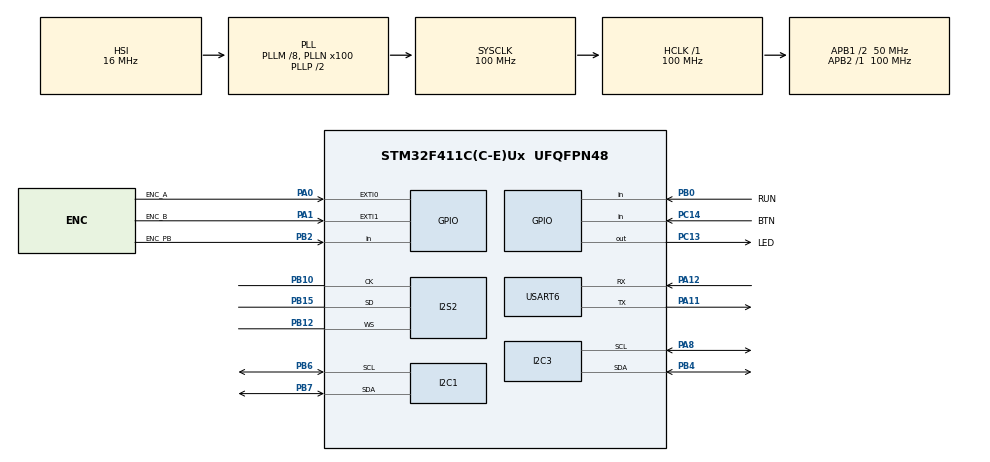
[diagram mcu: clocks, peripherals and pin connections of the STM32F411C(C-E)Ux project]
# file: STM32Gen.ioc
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Dma.Request0=SPI2_TX
Dma.SPI2_TX.0.Direction=DMA_MEMORY_TO_PERIPH
Dma.SPI2_TX.0.FIFOMode=DMA_FIFOMODE_DISABLE
Dma.SPI2_TX.0.Instance=DMA1_Stream4
Dma.SPI2_TX.0.MemDataAlignment=DMA_MDATAALIGN_HALFWORD
Dma.SPI2_TX.0.MemInc=DMA_MINC_ENABLE
Dma.SPI2_TX.0.Mode=DMA_CIRCULAR
Dma.SPI2_TX.0.PeriphDataAlignment=DMA_PDATAALIGN_HALFWORD
Dma.SPI2_TX.0.PeriphInc=DMA_PINC_DISABLE
Dma.SPI2_TX.0.Priority=DMA_PRIORITY_LOW
FREERTOS.Tasks01=defaultTask,24,512,StartDefaultTask,Default,NULL,Static,defaultTaskBuffer,defaultTaskControlBlock;waveGenTask,32,512,StartWaveGenTask,Default,NULL,Static,waveGenTaskBuffer,waveGenTaskControlBlock
FREERTOS.configUSE_NEWLIB_REENTRANT=1
I2C1.I2C_Mode=I2C_Fast
I2S2.AudioFreq=AudioFreqCustomValue
I2S2.AudioFreqCustom=40000
I2S2.ErrorAudioFreq=0.0 %
I2S2.FullDuplexMode=I2S_FULLDUPLEXMODE_DISABLE
I2S2.Instance=SPI$Index
I2S2.RealAudioFreq=40.0 KHz
I2S2.VirtualMode=I2S_MODE_MASTER
Mcu.Family=STM32F4
Mcu.Name=STM32F411C(C-E)Ux
Mcu.Package=UFQFPN48
NVIC.DMA1_Stream4_IRQn=true\:5\:0\:false\:false\:true\:true\:false\:true\:true
NVIC.EXTI0_IRQn=true\:5\:0\:false\:false\:true\:true\:true\:true\:true
NVIC.EXTI1_IRQn=true\:5\:0\:false\:false\:true\:true\:true\:true\:true
NVIC.PriorityGroup=NVIC_PRIORITYGROUP_4
NVIC.TIM1_UP_TIM10_IRQn=true\:15\:0\:false\:false\:true\:false\:false\:true\:true
NVIC.TimeBase=TIM1_UP_TIM10_IRQn
NVIC.TimeBaseIP=TIM10
PA0-WKUP.GPIO_Label=ENC_A
PA0-WKUP.GPIO_ModeDefaultEXTI=GPIO_MODE_IT_RISING_FALLING
PA0-WKUP.Signal=GPXTI0
PA1.GPIO_Label=ENC_B
PA1.GPIO_ModeDefaultEXTI=GPIO_MODE_IT_RISING_FALLING
PA1.Signal=GPXTI1
PA11.Mode=Asynchronous
PA11.Signal=USART6_TX
PA12.Mode=Asynchronous
PA12.Signal=USART6_RX
PA13.Mode=Serial_Wire
PA13.Signal=SYS_JTMS-SWDIO
PA14.Mode=Serial_Wire
PA14.Signal=SYS_JTCK-SWCLK
PA8.Mode=I2C
PA8.Signal=I2C3_SCL
PB0.GPIO_Label=RUN
PB0.GPIO_PuPd=GPIO_PULLDOWN
PB0.Signal=GPIO_Input
PB10.Mode=Half_Duplex_Master
PB10.Signal=I2S2_CK
PB12.Mode=Half_Duplex_Master
PB12.Signal=I2S2_WS
PB15.Mode=Half_Duplex_Master
PB15.Signal=I2S2_SD
PB2.GPIO_Label=ENC_PB
PB2.Signal=GPIO_Input
PB4.Mode=I2C
PB4.Signal=I2C3_SDA
PB6.Mode=I2C
PB6.Signal=I2C1_SCL
PB7.Mode=I2C
PB7.Signal=I2C1_SDA
PC13-ANTI_TAMP.GPIO_Label=LED
PC13-ANTI_TAMP.Signal=GPIO_Output
PC14-OSC32_IN.GPIO_Label=BTN
PC14-OSC32_IN.Signal=GPIO_Input
PH0\ -\ OSC_IN.Mode=HSE-External-Oscillator
PH0\ -\ OSC_IN.Signal=RCC_OSC_IN
PH1\ -\ OSC_OUT.Mode=HSE-External-Oscillator
PH1\ -\ OSC_OUT.Signal=RCC_OSC_OUT
ProjectManager.HeapSize=0x200
ProjectManager.StackSize=0x400
ProjectManager.TargetToolchain=STM32CubeIDE
RCC.48MHZClocksFreq_Value=50000000
RCC.AHBFreq_Value=100000000
RCC.APB1CLKDivider=RCC_HCLK_DIV2
RCC.APB1Freq_Value=50000000
RCC.APB1TimFreq_Value=100000000
RCC.APB2Freq_Value=100000000
RCC.APB2TimFreq_Value=100000000
RCC.CortexFreq_Value=100000000
RCC.HCLKFreq_Value=100000000
RCC.HSE_VALUE=25000000
RCC.HSI_VALUE=16000000
RCC.LSE_VALUE=32768
RCC.PLLM=8
RCC.PLLN=100
RCC.SYSCLKFreq_VALUE=100000000
RCC.SYSCLKSource=RCC_SYSCLKSOURCE_PLLCLK
RCC.VCOOutputFreq_Value=200000000
USART6.VirtualMode=VM_ASYNC
VP_FREERTOS_VS_CMSIS_V2.Mode=CMSIS_V2
VP_SYS_VS_tim10.Mode=TIM10
board=custom

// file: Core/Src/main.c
/* USER CODE BEGIN Header */
/**
  ******************************************************************************
  * @file           : main.c
  * @brief          : Main program body
  ******************************************************************************
  * @attention
  *
  * Copyright (c) 2026 STMicroelectronics.
  * All rights reserved.
  *
  * This software is licensed under terms that can be found in the LICENSE file
  * in the root directory of this software component.
  * If no LICENSE file comes with this software, it is provided AS-IS.
  *
  ******************************************************************************
  */
/* USER CODE END Header */
#include "main.h"
#include "cmsis_os.h"

/* USER CODE BEGIN Includes */
#include <stdio.h>

#include "DefaultTask.h"
#include "WaveGenTask.h"
/* USER CODE END Includes */

typedef StaticTask_t osStaticThreadDef_t;

I2C_HandleTypeDef hi2c1;
I2C_HandleTypeDef hi2c3;

I2S_HandleTypeDef hi2s2;
DMA_HandleTypeDef hdma_spi2_tx;

UART_HandleTypeDef huart6;

/* Definitions for defaultTask */
osThreadId_t defaultTaskHandle;
uint32_t defaultTaskBuffer[ 512 ];
osStaticThreadDef_t defaultTaskControlBlock;
const osThreadAttr_t defaultTask_attributes = {
  .name = "defaultTask",
  .cb_mem = &defaultTaskControlBlock,
  .cb_size = sizeof(defaultTaskControlBlock),
  .stack_mem = &defaultTaskBuffer[0],
  .stack_size = sizeof(defaultTaskBuffer),
  .priority = (osPriority_t) osPriorityNormal,
};
/* Definitions for waveGenTask */
osThreadId_t waveGenTaskHandle;
uint32_t waveGenTaskBuffer[ 512 ];
osStaticThreadDef_t waveGenTaskControlBlock;
const osThreadAttr_t waveGenTask_attributes = {
  .name = "waveGenTask",
  .cb_mem = &waveGenTaskControlBlock,
  .cb_size = sizeof(waveGenTaskControlBlock),
  .stack_mem = &waveGenTaskBuffer[0],
  .stack_size = sizeof(waveGenTaskBuffer),
  .priority = (osPriority_t) osPriorityAboveNormal,
};

void SystemClock_Config(void);
static void MX_GPIO_Init(void);
static void MX_DMA_Init(void);
static void MX_I2C1_Init(void);
static void MX_I2S2_Init(void);
static void MX_I2C3_Init(void);
static void MX_USART6_UART_Init(void);
void StartDefaultTask(void *argument);
void StartWaveGenTask(void *argument);

int main(void)
{

  /* MCU Configuration--------------------------------------------------------*/

  /* Reset of all peripherals, Initializes the Flash interface and the Systick. */
  HAL_Init();

  /* Configure the system clock */
  SystemClock_Config();

  /* Initialize all configured peripherals */
  MX_GPIO_Init();
  MX_DMA_Init();
  MX_I2C1_Init();
  MX_I2S2_Init();
  MX_I2C3_Init();
  MX_USART6_UART_Init();
  /* USER CODE BEGIN 2 */

  puts( "\x0cStarted\r\n" );
  fflush( stdout );
  /* USER CODE END 2 */

  /* Init scheduler */
  osKernelInitialize();

  /* Create the thread(s) */
  /* creation of defaultTask */
  defaultTaskHandle = osThreadNew(StartDefaultTask, NULL, &defaultTask_attributes);

  /* creation of waveGenTask */
  waveGenTaskHandle = osThreadNew(StartWaveGenTask, NULL, &waveGenTask_attributes);

  /* Start scheduler */
  osKernelStart();

  /* We should never get here as control is now taken by the scheduler */

  /* Infinite loop */
  while (1)
  {

  }
}

void SystemClock_Config(void)
{
  RCC_OscInitTypeDef RCC_OscInitStruct = {0};
  RCC_ClkInitTypeDef RCC_ClkInitStruct = {0};

  /** Configure the main internal regulator output voltage
  */
  __HAL_RCC_PWR_CLK_ENABLE();
  __HAL_PWR_VOLTAGESCALING_CONFIG(PWR_REGULATOR_VOLTAGE_SCALE1);

  /** Initializes the RCC Oscillators according to the specified parameters
  * in the RCC_OscInitTypeDef structure.
  */
  RCC_OscInitStruct.OscillatorType = RCC_OSCILLATORTYPE_HSI;
  RCC_OscInitStruct.HSIState = RCC_HSI_ON;
  RCC_OscInitStruct.HSICalibrationValue = RCC_HSICALIBRATION_DEFAULT;
  RCC_OscInitStruct.PLL.PLLState = RCC_PLL_ON;
  RCC_OscInitStruct.PLL.PLLSource = RCC_PLLSOURCE_HSI;
  RCC_OscInitStruct.PLL.PLLM = 8;
  RCC_OscInitStruct.PLL.PLLN = 100;
  RCC_OscInitStruct.PLL.PLLP = RCC_PLLP_DIV2;
  RCC_OscInitStruct.PLL.PLLQ = 4;
  if (HAL_RCC_OscConfig(&RCC_OscInitStruct) != HAL_OK)
  {
    Error_Handler();
  }

  /** Initializes the CPU, AHB and APB buses clocks
  */
  RCC_ClkInitStruct.ClockType = RCC_CLOCKTYPE_HCLK|RCC_CLOCKTYPE_SYSCLK
                              |RCC_CLOCKTYPE_PCLK1|RCC_CLOCKTYPE_PCLK2;
  RCC_ClkInitStruct.SYSCLKSource = RCC_SYSCLKSOURCE_PLLCLK;
  RCC_ClkInitStruct.AHBCLKDivider = RCC_SYSCLK_DIV1;
  RCC_ClkInitStruct.APB1CLKDivider = RCC_HCLK_DIV2;
  RCC_ClkInitStruct.APB2CLKDivider = RCC_HCLK_DIV1;

  if (HAL_RCC_ClockConfig(&RCC_ClkInitStruct, FLASH_LATENCY_3) != HAL_OK)
  {
    Error_Handler();
  }
}

static void MX_I2C1_Init(void)
{

  hi2c1.Instance = I2C1;
  hi2c1.Init.ClockSpeed = 400000;
  hi2c1.Init.DutyCycle = I2C_DUTYCYCLE_2;
  hi2c1.Init.OwnAddress1 = 0;
  hi2c1.Init.AddressingMode = I2C_ADDRESSINGMODE_7BIT;
  hi2c1.Init.DualAddressMode = I2C_DUALADDRESS_DISABLE;
  hi2c1.Init.OwnAddress2 = 0;
  hi2c1.Init.GeneralCallMode = I2C_GENERALCALL_DISABLE;
  hi2c1.Init.NoStretchMode = I2C_NOSTRETCH_DISABLE;
  if (HAL_I2C_Init(&hi2c1) != HAL_OK)
  {
    Error_Handler();
  }

}

static void MX_I2C3_Init(void)
{

  hi2c3.Instance = I2C3;
  hi2c3.Init.ClockSpeed = 100000;
  hi2c3.Init.DutyCycle = I2C_DUTYCYCLE_2;
  hi2c3.Init.OwnAddress1 = 0;
  hi2c3.Init.AddressingMode = I2C_ADDRESSINGMODE_7BIT;
  hi2c3.Init.DualAddressMode = I2C_DUALADDRESS_DISABLE;
  hi2c3.Init.OwnAddress2 = 0;
  hi2c3.Init.GeneralCallMode = I2C_GENERALCALL_DISABLE;
  hi2c3.Init.NoStretchMode = I2C_NOSTRETCH_DISABLE;
  if (HAL_I2C_Init(&hi2c3) != HAL_OK)
  {
    Error_Handler();
  }

}

static void MX_I2S2_Init(void)
{

  hi2s2.Instance = SPI2;
  hi2s2.Init.Mode = I2S_MODE_MASTER_TX;
  hi2s2.Init.Standard = I2S_STANDARD_PHILIPS;
  hi2s2.Init.DataFormat = I2S_DATAFORMAT_16B;
  hi2s2.Init.MCLKOutput = I2S_MCLKOUTPUT_DISABLE;
  hi2s2.Init.AudioFreq = 40000;
  hi2s2.Init.CPOL = I2S_CPOL_LOW;
  hi2s2.Init.ClockSource = I2S_CLOCK_PLL;
  hi2s2.Init.FullDuplexMode = I2S_FULLDUPLEXMODE_DISABLE;
  if (HAL_I2S_Init(&hi2s2) != HAL_OK)
  {
    Error_Handler();
  }

}

static void MX_USART6_UART_Init(void)
{

  huart6.Instance = USART6;
  huart6.Init.BaudRate = 115200;
  huart6.Init.WordLength = UART_WORDLENGTH_8B;
  huart6.Init.StopBits = UART_STOPBITS_1;
  huart6.Init.Parity = UART_PARITY_NONE;
  huart6.Init.Mode = UART_MODE_TX_RX;
  huart6.Init.HwFlowCtl = UART_HWCONTROL_NONE;
  huart6.Init.OverSampling = UART_OVERSAMPLING_16;
  if (HAL_UART_Init(&huart6) != HAL_OK)
  {
    Error_Handler();
  }

}

static void MX_DMA_Init(void)
{

  /* DMA controller clock enable */
  __HAL_RCC_DMA1_CLK_ENABLE();

  /* DMA interrupt init */
  /* DMA1_Stream4_IRQn interrupt configuration */
  HAL_NVIC_SetPriority(DMA1_Stream4_IRQn, 5, 0);
  HAL_NVIC_EnableIRQ(DMA1_Stream4_IRQn);

}

static void MX_GPIO_Init(void)
{
  LL_EXTI_InitTypeDef EXTI_InitStruct = {0};
  LL_GPIO_InitTypeDef GPIO_InitStruct = {0};

  /* GPIO Ports Clock Enable */
  LL_AHB1_GRP1_EnableClock(LL_AHB1_GRP1_PERIPH_GPIOC);
  LL_AHB1_GRP1_EnableClock(LL_AHB1_GRP1_PERIPH_GPIOH);
  LL_AHB1_GRP1_EnableClock(LL_AHB1_GRP1_PERIPH_GPIOA);
  LL_AHB1_GRP1_EnableClock(LL_AHB1_GRP1_PERIPH_GPIOB);

  /**/
  LL_GPIO_ResetOutputPin(LED_GPIO_Port, LED_Pin);

  /**/
  GPIO_InitStruct.Pin = LED_Pin;
  GPIO_InitStruct.Mode = LL_GPIO_MODE_OUTPUT;
  GPIO_InitStruct.Speed = LL_GPIO_SPEED_FREQ_LOW;
  GPIO_InitStruct.OutputType = LL_GPIO_OUTPUT_PUSHPULL;
  GPIO_InitStruct.Pull = LL_GPIO_PULL_NO;
  LL_GPIO_Init(LED_GPIO_Port, &GPIO_InitStruct);

  /**/
  GPIO_InitStruct.Pin = BTN_Pin;
  GPIO_InitStruct.Mode = LL_GPIO_MODE_INPUT;
  GPIO_InitStruct.Pull = LL_GPIO_PULL_NO;
  LL_GPIO_Init(BTN_GPIO_Port, &GPIO_InitStruct);

  /**/
  GPIO_InitStruct.Pin = RUN_Pin;
  GPIO_InitStruct.Mode = LL_GPIO_MODE_INPUT;
  GPIO_InitStruct.Pull = LL_GPIO_PULL_DOWN;
  LL_GPIO_Init(RUN_GPIO_Port, &GPIO_InitStruct);

  /**/
  GPIO_InitStruct.Pin = ENC_PB_Pin;
  GPIO_InitStruct.Mode = LL_GPIO_MODE_INPUT;
  GPIO_InitStruct.Pull = LL_GPIO_PULL_NO;
  LL_GPIO_Init(ENC_PB_GPIO_Port, &GPIO_InitStruct);

  /**/
  LL_SYSCFG_SetEXTISource(LL_SYSCFG_EXTI_PORTA, LL_SYSCFG_EXTI_LINE0);

  /**/
  LL_SYSCFG_SetEXTISource(LL_SYSCFG_EXTI_PORTA, LL_SYSCFG_EXTI_LINE1);

  /**/
  EXTI_InitStruct.Line_0_31 = LL_EXTI_LINE_0;
  EXTI_InitStruct.LineCommand = ENABLE;
  EXTI_InitStruct.Mode = LL_EXTI_MODE_IT;
  EXTI_InitStruct.Trigger = LL_EXTI_TRIGGER_RISING_FALLING;
  LL_EXTI_Init(&EXTI_InitStruct);

  /**/
  EXTI_InitStruct.Line_0_31 = LL_EXTI_LINE_1;
  EXTI_InitStruct.LineCommand = ENABLE;
  EXTI_InitStruct.Mode = LL_EXTI_MODE_IT;
  EXTI_InitStruct.Trigger = LL_EXTI_TRIGGER_RISING_FALLING;
  LL_EXTI_Init(&EXTI_InitStruct);

  /**/
  LL_GPIO_SetPinPull(ENC_A_GPIO_Port, ENC_A_Pin, LL_GPIO_PULL_NO);

  /**/
  LL_GPIO_SetPinPull(ENC_B_GPIO_Port, ENC_B_Pin, LL_GPIO_PULL_NO);

  /**/
  LL_GPIO_SetPinMode(ENC_A_GPIO_Port, ENC_A_Pin, LL_GPIO_MODE_INPUT);

  /**/
  LL_GPIO_SetPinMode(ENC_B_GPIO_Port, ENC_B_Pin, LL_GPIO_MODE_INPUT);

  /* EXTI interrupt init*/
  NVIC_SetPriority(EXTI0_IRQn, NVIC_EncodePriority(NVIC_GetPriorityGrouping(),5, 0));
  NVIC_EnableIRQ(EXTI0_IRQn);
  NVIC_SetPriority(EXTI1_IRQn, NVIC_EncodePriority(NVIC_GetPriorityGrouping(),5, 0));
  NVIC_EnableIRQ(EXTI1_IRQn);

}

/* USER CODE BEGIN 4 */
int _write(int file, char *ptr, int len)
{
  HAL_UART_Transmit(&huart6, (uint8_t*)ptr, len, HAL_MAX_DELAY);
  return len;
}
/* USER CODE END 4 */

void StartDefaultTask(void *argument)
{
  /* USER CODE BEGIN 5 */
  DefaultTaskExecute();
  /* USER CODE END 5 */
}

void StartWaveGenTask(void *argument)
{
  /* USER CODE BEGIN StartWaveGenTask */
  WaveGenTaskExecute( waveGenTaskHandle );
  /* USER CODE END StartWaveGenTask */
}

void HAL_TIM_PeriodElapsedCallback(TIM_HandleTypeDef *htim)
{
  if (htim->Instance == TIM10)
  {
    HAL_IncTick();
  }
}

void Error_Handler(void)
{
  __disable_irq();
  while (1)
  {
  }
}
